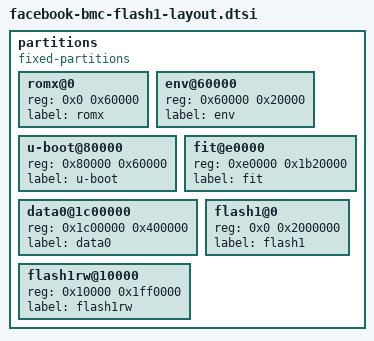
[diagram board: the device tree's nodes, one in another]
// SPDX-License-Identifier: GPL-2.0+
// Copyright (c) 2018 Facebook Inc.

partitions {
	compatible = "fixed-partitions";
	#address-cells = <1>;
	#size-cells = <1>;

	romx@0 {
		reg = <0x0 0x60000>;
		label = "romx";
	};
	env@60000 {
		reg = <0x60000 0x20000>;
		label = "env";
	};
	u-boot@80000 {
		reg = <0x80000 0x60000>;
		label = "u-boot";
	};
	fit@e0000 {
		reg = <0xe0000 0x1b20000>;
		label = "fit";
	};

	/*
	 * "data0" partition is used by several Facebook BMC platforms
	 * as persistent data store.
	 */
	data0@1c00000 {
		reg = <0x1c00000 0x400000>;
		label = "data0";
	};

	/*
	 * Although the master partition can be created by enabling
	 * MTD_PARTITIONED_MASTER option, below "flash1" and "flash1rw" partition is
	 * explicitly created to avoid breaking legacy applications.
	 */
	flash1@0 {
		reg = <0x0 0x2000000>;
		label = "flash1";
	};
	flash1rw@10000 {
		reg = <0x10000 0x1ff0000>;
		label = "flash1rw";
	};
};
